# BlueNRG1 register map
Vendor: STMicroelectronics; Series: BlueNRG1; File version: 2.0.0
CPU: CM0 r0p0, little endian, no MPU, no FPU, 2 interrupt priority bits
Registers are 32-bit, read-write, reset 0x0 unless marked. A register's access mark holds for its fields unless they carry their own. Offsets are from the block's base; [hi:lo] are bit positions; {n}, {i} and the like mark numbered series.

## RTC — Real-Time Counter
Base 0x40F00000
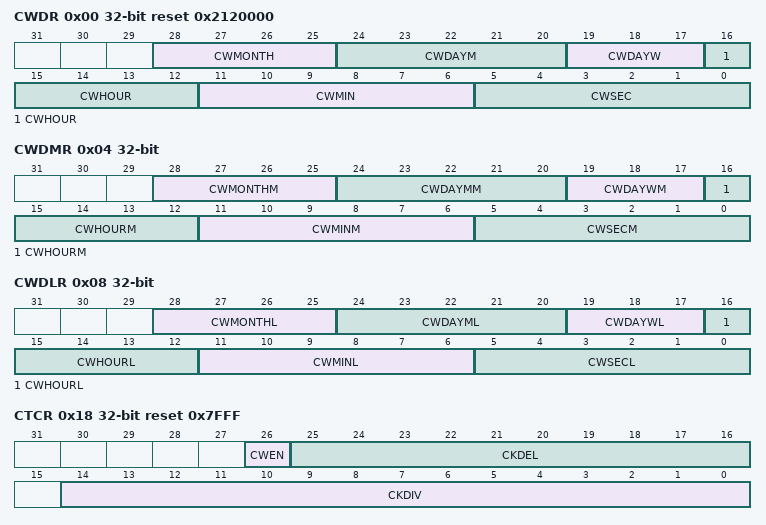
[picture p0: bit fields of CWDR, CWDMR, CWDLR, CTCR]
0x00 CWDR ro reset 0x2120000 — Clockwatch Data Register
  [28:25] CWMONTH — RTC clockwatch month value:<ul><li>0001b: January.</li><li>...</li><li>1100: December.</li></ul>
  [24:20] CWDAYM — RTC clockwatch day of month value: 1 to 28/29/30 or 31. Range of value to program depends on the month:<ul><li>1 to 28: February month, non-leap year.</li><li>1 to 29: February month, leap year.</li><li>1 to 30: April, June, September, November month.</li><li>1 to 31: January, March, May, August, October, December month.</li></ul>
  [19:17] CWDAYW — RTC clockwatch day of week value. Clockwatch day of week:<ul><li>001b: Sunday.</li><li>010b: Monday.</li><li>011b: Tuesday.</li><li>100b: Wednesday.</li><li>101b: Thursday.</li><li>110b: Friday.</li><li>111b: Saturday.</li></ul>
  [16:12] CWHOUR — RTC clockwatch hour value. Clockwatch seconds: 0 to 23 (max 0x17).
  [11:6] CWMIN — RTC clockwatch minute value. Clockwatch seconds: 0 to 59 (max 0x3B).
  [5:0] CWSEC — RTC clockwatch second value. Clockwatch seconds: 0 to 59 (max 0x3B).
0x04 CWDMR — Clockwatch Data Match Register
  [28:25] CWMONTHM — RTC clockwatch month match value:<ul><li>0000b: (day of month is don't care in the comparison. Default value after PORn).</li><li>0001b to 1100b: (1 to 12) month match value.</li><li>1101b (13, 0xD) to 1111b (0xF) non-valid data, match never occurs.</li></ul>
  [24:20] CWDAYMM — RTC clockwatch day of month match value:<ul><li>0000b: (month is don't care in the comparison. Default value after PORn).</li><li>1 to 31: day of month match value.</li></ul>
  [19:17] CWDAYWM — RTC clockwatch day of week match value:<ul><li>000b: day of week is don't care in the comparison. (Default value after PORn).</li><li>001b to 111b: (1 to 7) day of week match value.</li></ul>
  [16:12] CWHOURM — RTC clockwatch hour match value:<ul><li>00000b to 10111b: (0 to 23 or 0x00 to 0x17) hour match value.</li><li>11000b to 11111b - (24 to 31 or 0x18 to 0x1F).</li></ul>Non-valid data, match never occurs.
  [11:6] CWMINM — RTC clockwatch minute match value:<ul><li>00 0000 to 11 1011: (0 to 59 or 0x00 to 0x3B) clockwatch minutes.</li><li>11 1100 to 11 1111 - (60 to 63 or 0x3C to 0x3F).</li></ul>Non-valid data, match never occurs.
  [5:0] CWSECM — RTC clockwatch second match value:<ul><li>00 0000 to 11 1011: (0 to 59 or 0x00 to 0x3B) clockwatch seconds.</li><li>11 1100 to 11 1111 - (60 to 63 or 0x3C to 0x3F).</li></ul>Non-valid data, match never occurs.
0x08 CWDLR — Clockwatch Data Load Register
  [28:25] CWMONTHL — RTC clockwatch month load value:<ul><li>0001b: January.</li><li>...</li><li>1100: December.</li></ul>Other values must not be used.
  [24:20] CWDAYML — RTC clockwatch day of month load value. 1 to 28/29/30 or 31 depending on month:<ul><li>1 to 28: February month, non-leap year.</li><li>1 to 29: February month, leap year.</li><li>1 to 30: April, June, September, November month.</li><li>1 to 31: January, March, May, August, October, December month.</li><li>Other values must not be used.</li></ul>
  [19:17] CWDAYWL — RTC clockwatch day of week load value. Clockwatch day of week:<ul><li>000b: Must not be used.</li><li>001b: Sunday.</li><li>010b: Monday.</li><li>011b: Tuesday.</li><li>100b: Wednesday.</li><li>101b: Thursday.</li><li>110b: Friday.</li><li>111b: Saturday.</li></ul>
  [16:12] CWHOURL — RTC clockwatch hour load value. Clockwatch hours from 0 to 23 (0x17). Other values must not be used.
  [11:6] CWMINL — RTC clockwatch minute load value. Clockwatch minutes from 0 to 59 (0x3B). Other values must not be used.
  [5:0] CWSECL — RTC clockwatch second load value. Clockwatch seconds from 0 to 59 (0x3B). Other values must not be used.
0x0C CWYR 16-bit ro reset 0x2000 — Clockwatch Year Register
  [13:0] CWYEAR — RTC clockwatch year value. Clockwatch year, in BCD format is from 0 to 3999.
0x10 CWYMR 16-bit reset 0x2000 — Clockwatch Year Match Register
  [13:0] CWYEARM — RTC clockwatch year match value. Clockwatch year match value is in BCD format from 0 to 3999.
0x14 CWYLR 16-bit — Clockwatch Year Load Register
  [13:0] CWYEARL — RTC clockwatch year load value. Clockwatch year load value is in BCD format from 0 to 3999.
0x18 CTCR reset 0x7FFF — Control Trim and Counter Register
  [26] CWEN — Clockwatch enable bit. When set to 1, the clockwatch is enabled. Once it is enabled, any write to this register has no effect until a power-on reset. A read returns the value of the CWEN bit value.
  [25:16] CKDEL — Trim delete count. This value represents the number of CLK32K clock pulses to delete every 1023 CLK32K clock cycles to get a better reference 1 Hz clock for incrementing the RTC counter.<ul><li>0x000: No CLK32K clock cycle is deleted every 1023 CLK1HZ clock cycles (default value after PORn reset).</li><li>0x001: 1 CLK32K clock cycle is deleted every 1023 CLK1HZ clock cycles.</li><li>...</li><li>0x3FF: 1023 CLK32K clock cycles are deleted every 1023 CLK1HZ clock cycles.</li></ul>Writing to this bit-field will be disregarded if CWEN = 1. A read returns the value of the CKDEL bit-field.
  [14:0] CKDIV — Clock divider factor. This value plus one represents the integer part of the CLK32K clock divider used to produce the reference 1 Hz clock.<ul><li>0x000: CLK1HZ clock is similar to CLK32K for RTC timer and stopped for RTC clockwatch.</li><li>0x0001: 2 CLK32K clock cycles per CLK1HZ clock cycle.</li><li>...</li><li>0x7FFF: 32768 CLK32K clock cycles per CLK1HZ clock cycle (default value after PORn reset).</li><li>...</li><li>0xFFFF: CLK32K clock cycles per CLK1HZ clock cycle.</li></ul>Writing to this bit-field will be disregarded if CWEN = 1. A read returns the value of the CKDIV bit-field.
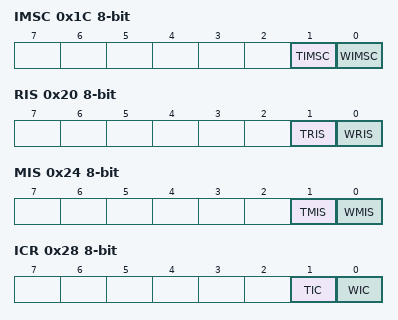
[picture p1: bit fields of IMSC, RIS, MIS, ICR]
0x1C IMSC 8-bit — RTC interrupt mask register
  [1] TIMSC — RTC timer interrupt enable bit:<ul><li>When set to 0, sets the mask for RTC timer interrupt (default after PORn reset). The interrupt is disabled.</li><li>When set to 1, clears this mask and enables the interrupt.</li></ul>
  [0] WIMSC — RTC clock watch interrupt enable bit:<ul><li>When set to 0, clears the interrupt mask (default after PORn reset). The interrupt is disabled.</li><li>When set to 1, the interrupt for RTC clockwatch interrupt is enabled.</li></ul>
0x20 RIS 8-bit ro — RTC raw interrupt status register
  [1] TRIS — RTC timer raw interrupt status bit. Gives the raw interrupt state (prior to masking) of the RTC timer interrupt.
  [0] WRIS — RTC clock watch raw interrupt status bit. Gives the raw interrupt state (prior to masking) of the RTC clock watch interrupt.
0x24 MIS 8-bit ro — RTC masked interrupt status register
  [1] TMIS — RTC timer interrupt status bit. Gives the masked interrupt status (after masking) of the RTC timer interrupt TINTR.
  [0] WMIS — RTC clock watch interrupt status bit. Gives the masked interrupt status (after masking) of the RTC clock watch interrupt WINTR.
0x28 ICR 8-bit wo (reset mask 0x1) write-1-clears — RTC interrupt clear register
  [1] TIC — RTC timer interrupt clear register bit. Clears the RTC timer interrupt TINTR.<ul><li>0: No effect.</li><li>1: Clears the interrupt.</li></ul>
  [0] WIC — RTC clock watch interrupt clear register bit. Clears the RTC clock watch interrupt WINTR.<ul><li>0: No effect.</li><li>1: Clears the interrupt.</li></ul>
0x2C TDR ro reset 0xFFFFFFFF — RTC timer load value
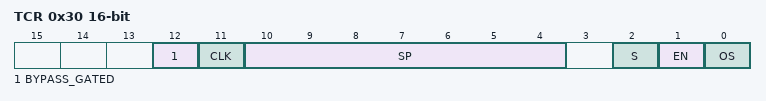
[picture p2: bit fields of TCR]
0x30 TCR 16-bit — RTC timer control register
  [12] BYPASS_GATED — Enable or disable the internal clock gating:<ul><li>0: The internal clock gating is activated.</li><li>1: No clock gating, clock is always enabled.</li></ul>
  [11] CLK — RTC Timer clock.<ul><li>0: The RTC timer is clocked by CLK32K.</li><li>1: The RTC timer is clocked by the trimmed clock.</li></ul>
    0=KHZ32_CLK (RTC timer is clocked by CLK32K); 1=TRIMMED_CLK (RTC timer is clocked by the trimmed clock)
  [10:4] SP — RTC Timer Pattern size. Number of pattern bits crossed by the pointer. It defines the useful pattern size.
  [2] S — RTC Timer self start bit. When written to 1b, each write in a load register or a pattern will set EN to 1b, so, start the counter in the next CLK32K cycle.
  [1] EN — RTC Timer enable bit.<ul><li>0: The RTC timer is stopped on the next CLK32K cycle.</li><li>1: The RTC timer is enabled on the next CLK32K cycle.</li></ul>When the RTC timer is stopped, the content of the counter is frozen. A read returns the value of the EN bit. This bit set by hardware when the TLR register is written to while the counter is stopped. When the device is active, this bit is cleared by hardware when the counter reaches zero in one-shot mode.
  [0] OS — RTC Timer one shot count.<ul><li>0: Periodic mode (default). When reaching zero, the RTC timer raises its interrupt and is reloaded from the LD content.</li><li>1: One-shot mode. When reaching zero, the RTC timer raise its interrupt and stops.</li></ul>
0x34 TLR1 — RTC Timer first Load Register
0x38 TLR2 — RTC Timer second Load Register
{0x38+4i} TPR{i} (i=1..4) — RTC Timer Pattern Register (pattern[{32i-1}:{32i-32}])
0x4C TIN — RTC Timer Interrupt Number Register

## Notices in the file
License
